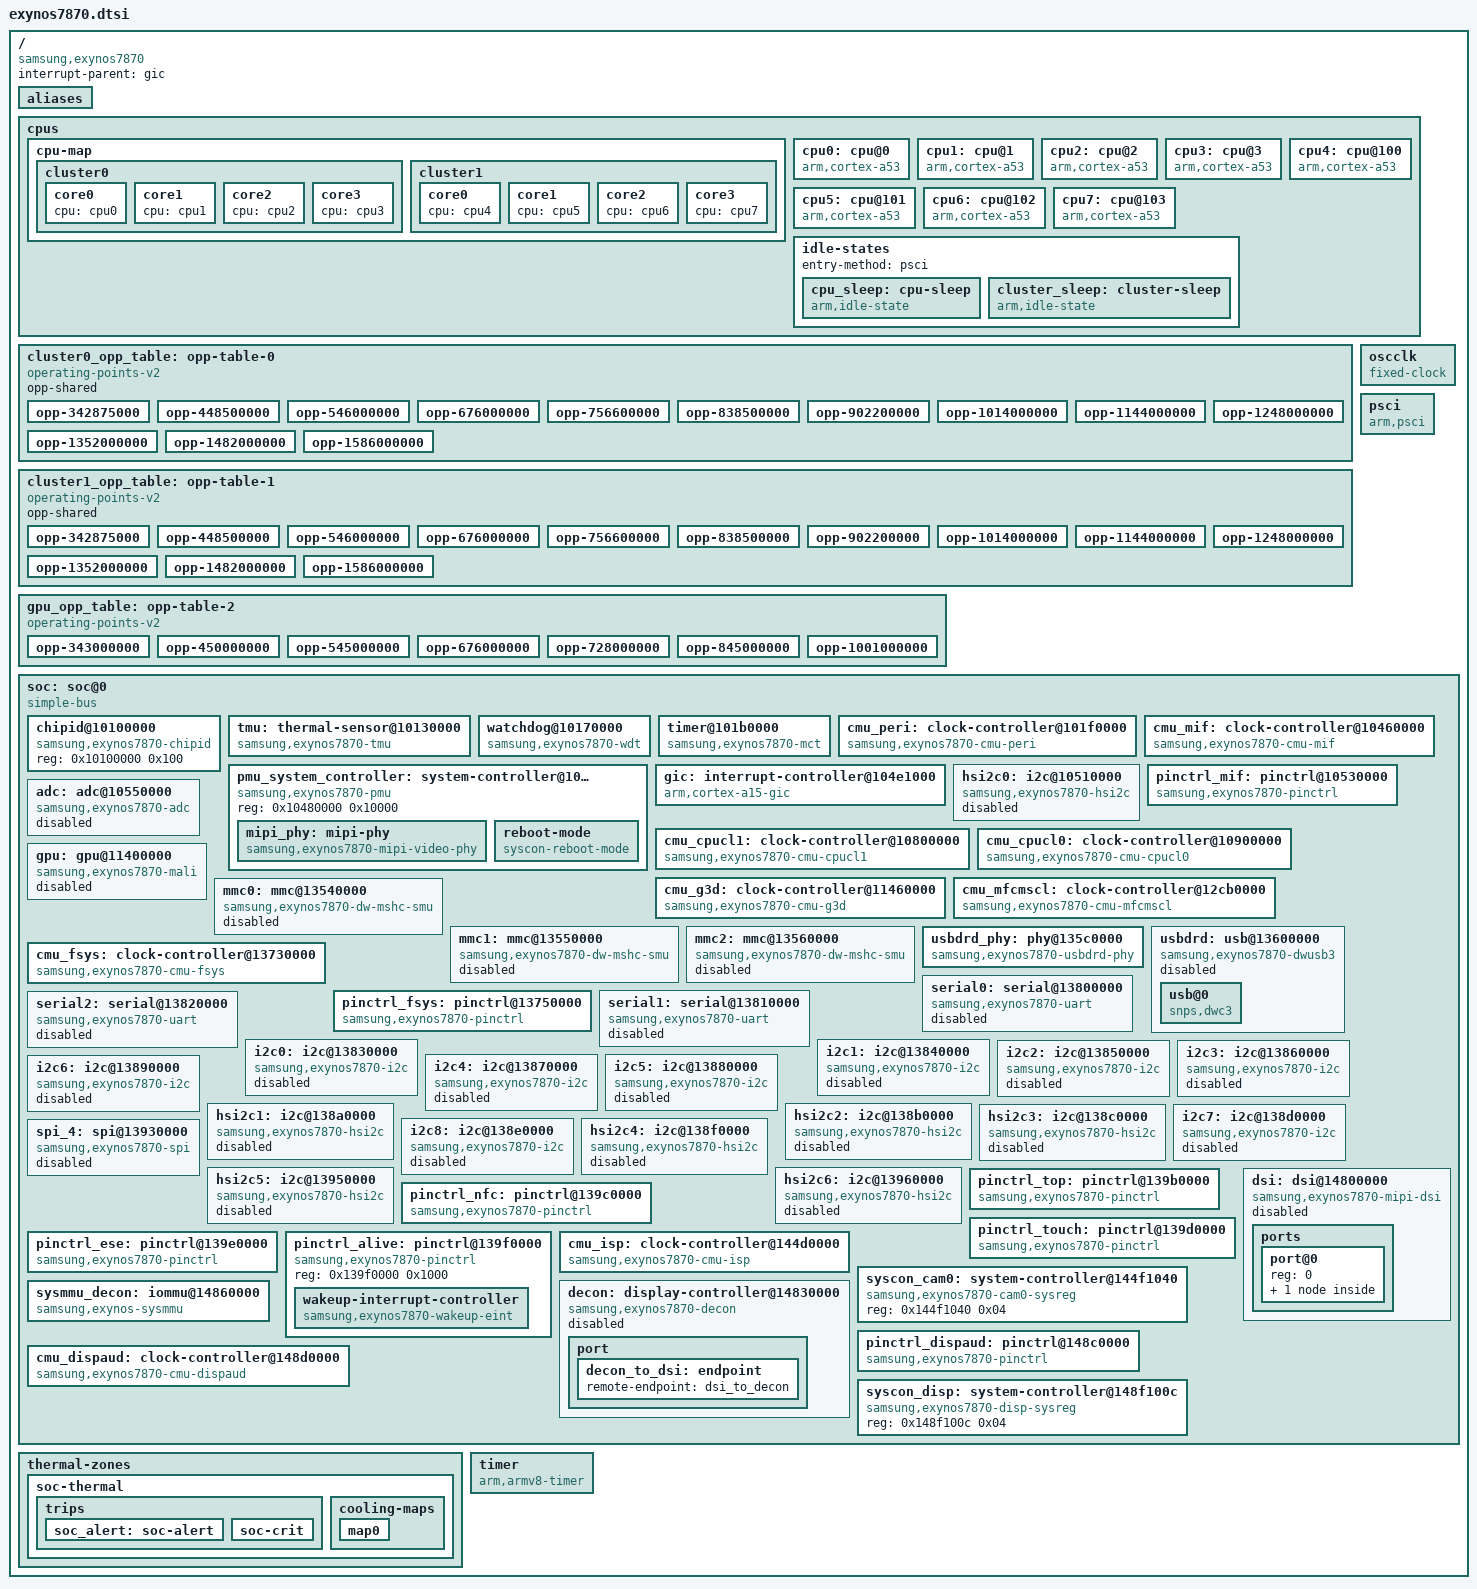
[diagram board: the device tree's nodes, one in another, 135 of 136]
// SPDX-License-Identifier: GPL-2.0
/*
 * Samsung Exynos7870 SoC device tree source
 *
 * Copyright (c) 2015 Samsung Electronics Co., Ltd.
 * Copyright (c) 2025 Kaustabh Chakraborty <kauschluss@disroot.org>
 */

#include <dt-bindings/clock/samsung,exynos7870-cmu.h>
#include <dt-bindings/interrupt-controller/arm-gic.h>
#include <dt-bindings/thermal/thermal.h>

/ {
	compatible = "samsung,exynos7870";
	#address-cells = <2>;
	#size-cells = <1>;

	interrupt-parent = <&gic>;

	aliases {
		pinctrl0 = &pinctrl_alive;
		pinctrl1 = &pinctrl_dispaud;
		pinctrl2 = &pinctrl_ese;
		pinctrl3 = &pinctrl_fsys;
		pinctrl4 = &pinctrl_mif;
		pinctrl5 = &pinctrl_nfc;
		pinctrl6 = &pinctrl_top;
		pinctrl7 = &pinctrl_touch;
	};

	cpus {
		#address-cells = <1>;
		#size-cells = <0>;

		cpu-map {
			cluster0 {
				core0 {
					cpu = <&cpu0>;
				};

				core1 {
					cpu = <&cpu1>;
				};

				core2 {
					cpu = <&cpu2>;
				};

				core3 {
					cpu = <&cpu3>;
				};
			};

			cluster1 {
				core0 {
					cpu = <&cpu4>;
				};

				core1 {
					cpu = <&cpu5>;
				};

				core2 {
					cpu = <&cpu6>;
				};

				core3 {
					cpu = <&cpu7>;
				};
			};
		};

		cpu0: cpu@0 {
			device_type = "cpu";
			compatible = "arm,cortex-a53";
			reg = <0x0>;
			clocks = <&cmu_cpucl0 CLK_CLUSTER0_SCLK>;
			cpu-idle-states = <&cpu_sleep>;
			enable-method = "psci";
			operating-points-v2 = <&cluster0_opp_table>;
			#cooling-cells = <2>;
		};

		cpu1: cpu@1 {
			device_type = "cpu";
			compatible = "arm,cortex-a53";
			reg = <0x1>;
			clocks = <&cmu_cpucl0 CLK_CLUSTER0_SCLK>;
			cpu-idle-states = <&cpu_sleep>;
			enable-method = "psci";
			operating-points-v2 = <&cluster0_opp_table>;
			#cooling-cells = <2>;
		};

		cpu2: cpu@2 {
			device_type = "cpu";
			compatible = "arm,cortex-a53";
			reg = <0x2>;
			clocks = <&cmu_cpucl0 CLK_CLUSTER0_SCLK>;
			cpu-idle-states = <&cpu_sleep>;
			enable-method = "psci";
			operating-points-v2 = <&cluster0_opp_table>;
			#cooling-cells = <2>;
		};

		cpu3: cpu@3 {
			device_type = "cpu";
			compatible = "arm,cortex-a53";
			reg = <0x3>;
			clocks = <&cmu_cpucl0 CLK_CLUSTER0_SCLK>;
			cpu-idle-states = <&cpu_sleep>;
			enable-method = "psci";
			operating-points-v2 = <&cluster0_opp_table>;
			#cooling-cells = <2>;
		};

		cpu4: cpu@100 {
			device_type = "cpu";
			compatible = "arm,cortex-a53";
			reg = <0x100>;
			clocks = <&cmu_cpucl1 CLK_CLUSTER1_SCLK>;
			cpu-idle-states = <&cpu_sleep>, <&cluster_sleep>;
			enable-method = "psci";
			operating-points-v2 = <&cluster1_opp_table>;
			#cooling-cells = <2>;
		};

		cpu5: cpu@101 {
			device_type = "cpu";
			compatible = "arm,cortex-a53";
			reg = <0x101>;
			clocks = <&cmu_cpucl1 CLK_CLUSTER1_SCLK>;
			cpu-idle-states = <&cpu_sleep>, <&cluster_sleep>;
			enable-method = "psci";
			operating-points-v2 = <&cluster1_opp_table>;
			#cooling-cells = <2>;
		};

		cpu6: cpu@102 {
			device_type = "cpu";
			compatible = "arm,cortex-a53";
			reg = <0x102>;
			clocks = <&cmu_cpucl1 CLK_CLUSTER1_SCLK>;
			cpu-idle-states = <&cpu_sleep>, <&cluster_sleep>;
			enable-method = "psci";
			operating-points-v2 = <&cluster1_opp_table>;
			#cooling-cells = <2>;
		};

		cpu7: cpu@103 {
			device_type = "cpu";
			compatible = "arm,cortex-a53";
			reg = <0x103>;
			clocks = <&cmu_cpucl1 CLK_CLUSTER1_SCLK>;
			cpu-idle-states = <&cpu_sleep>, <&cluster_sleep>;
			enable-method = "psci";
			operating-points-v2 = <&cluster1_opp_table>;
			#cooling-cells = <2>;
		};

		idle-states {
			entry-method = "psci";

			cpu_sleep: cpu-sleep {
				compatible = "arm,idle-state";
				arm,psci-suspend-param = <0x10000>;
				local-timer-stop;
				entry-latency-us = <35>;
				exit-latency-us = <90>;
				min-residency-us = <750>;
			};

			cluster_sleep: cluster-sleep {
				compatible = "arm,idle-state";
				arm,psci-suspend-param = <0x1010000>;
				local-timer-stop;
				entry-latency-us = <150>;
				exit-latency-us = <250>;
				min-residency-us = <3000>;
			};
		};
	};

	cluster0_opp_table: opp-table-0 {
		compatible = "operating-points-v2";
		opp-shared;

		opp-342875000 {
			opp-hz = /bits/ 64 <342875000>;
			opp-microvolt = <687500 687500 1175000>;
			clock-latency-ns = <100000>;
		};

		opp-448500000 {
			opp-hz = /bits/ 64 <448500000>;
			opp-microvolt = <712500 712500 1175000>;
			clock-latency-ns = <100000>;
		};

		opp-546000000 {
			opp-hz = /bits/ 64 <546000000>;
			opp-microvolt = <743750 743750 1175000>;
			clock-latency-ns = <100000>;
		};

		opp-676000000 {
			opp-hz = /bits/ 64 <676000000>;
			opp-microvolt = <775000 775000 1175000>;
			clock-latency-ns = <100000>;
		};

		opp-756600000 {
			opp-hz = /bits/ 64 <756600000>;
			opp-microvolt = <806250 806250 1175000>;
			clock-latency-ns = <100000>;
		};

		opp-838500000 {
			opp-hz = /bits/ 64 <838500000>;
			opp-microvolt = <837500 837500 1175000>;
			clock-latency-ns = <100000>;
		};

		opp-902200000 {
			opp-hz = /bits/ 64 <902200000>;
			opp-microvolt = <875000 875000 1175000>;
			clock-latency-ns = <100000>;
		};

		opp-1014000000 {
			opp-hz = /bits/ 64 <1014000000>;
			opp-microvolt = <900000 900000 1175000>;
			clock-latency-ns = <100000>;
		};

		opp-1144000000 {
			opp-hz = /bits/ 64 <1144000000>;
			opp-microvolt = <950000 950000 1175000>;
			clock-latency-ns = <100000>;
		};

		opp-1248000000 {
			opp-hz = /bits/ 64 <1248000000>;
			opp-microvolt = <1000000 1000000 1175000>;
			clock-latency-ns = <100000>;
		};

		opp-1352000000 {
			opp-hz = /bits/ 64 <1352000000>;
			opp-microvolt = <1050000 1050000 1175000>;
			clock-latency-ns = <100000>;
		};

		opp-1482000000 {
			opp-hz = /bits/ 64 <1482000000>;
			opp-microvolt = <1112500 1112500 1175000>;
			clock-latency-ns = <100000>;
		};

		opp-1586000000 {
			opp-hz = /bits/ 64 <1586000000>;
			opp-microvolt = <1175000 1175000 1175000>;
			clock-latency-ns = <100000>;
		};
	};

	cluster1_opp_table: opp-table-1 {
		compatible = "operating-points-v2";
		opp-shared;

		opp-342875000 {
			opp-hz = /bits/ 64 <342875000>;
			opp-microvolt = <687500 687500 1175000>;
			clock-latency-ns = <100000>;
		};

		opp-448500000 {
			opp-hz = /bits/ 64 <448500000>;
			opp-microvolt = <712500 712500 1175000>;
			clock-latency-ns = <100000>;
		};

		opp-546000000 {
			opp-hz = /bits/ 64 <546000000>;
			opp-microvolt = <743750 743750 1175000>;
			clock-latency-ns = <100000>;
		};

		opp-676000000 {
			opp-hz = /bits/ 64 <676000000>;
			opp-microvolt = <775000 775000 1175000>;
			clock-latency-ns = <100000>;
		};

		opp-756600000 {
			opp-hz = /bits/ 64 <756600000>;
			opp-microvolt = <806250 806250 1175000>;
			clock-latency-ns = <100000>;
		};

		opp-838500000 {
			opp-hz = /bits/ 64 <838500000>;
			opp-microvolt = <837500 837500 1175000>;
			clock-latency-ns = <100000>;
		};

		opp-902200000 {
			opp-hz = /bits/ 64 <902200000>;
			opp-microvolt = <875000 875000 1175000>;
			clock-latency-ns = <100000>;
		};

		opp-1014000000 {
			opp-hz = /bits/ 64 <1014000000>;
			opp-microvolt = <900000 900000 1175000>;
			clock-latency-ns = <100000>;
		};

		opp-1144000000 {
			opp-hz = /bits/ 64 <1144000000>;
			opp-microvolt = <950000 950000 1175000>;
			clock-latency-ns = <100000>;
		};

		opp-1248000000 {
			opp-hz = /bits/ 64 <1248000000>;
			opp-microvolt = <1000000 1000000 1175000>;
			clock-latency-ns = <100000>;
		};

		opp-1352000000 {
			opp-hz = /bits/ 64 <1352000000>;
			opp-microvolt = <1050000 1050000 1175000>;
			clock-latency-ns = <100000>;
		};

		opp-1482000000 {
			opp-hz = /bits/ 64 <1482000000>;
			opp-microvolt = <1112500 1112500 1175000>;
			clock-latency-ns = <100000>;
		};

		opp-1586000000 {
			opp-hz = /bits/ 64 <1586000000>;
			opp-microvolt = <1175000 1175000 1175000>;
			clock-latency-ns = <100000>;
		};
	};

	oscclk: oscclk {
		compatible = "fixed-clock";
		#clock-cells = <0>;
	};

	gpu_opp_table: opp-table-2 {
		compatible = "operating-points-v2";

		opp-343000000 {
			opp-hz = /bits/ 64 <343000000>;
			opp-microvolt = <750000 750000 1006250>;
		};

		opp-450000000 {
			opp-hz = /bits/ 64 <450000000>;
			opp-microvolt = <750000 750000 1006250>;
		};

		opp-545000000 {
			opp-hz = /bits/ 64 <545000000>;
			opp-microvolt = <750000 750000 1006250>;
		};

		opp-676000000 {
			opp-hz = /bits/ 64 <676000000>;
			opp-microvolt = <812500 812500 1006250>;
		};

		opp-728000000 {
			opp-hz = /bits/ 64 <728000000>;
			opp-microvolt = <875000 875000 1006250>;
		};

		opp-845000000 {
			opp-hz = /bits/ 64 <845000000>;
			opp-microvolt = <925000 925000 1006250>;
		};

		opp-1001000000 {
			opp-hz = /bits/ 64 <1001000000>;
			opp-microvolt = <1006250 1006250 1006250>;
		};
	};

	psci {
		compatible = "arm,psci";
		method = "smc";
		cpu_suspend = <0xc4000001>;
		cpu_off = <0x84000002>;
		cpu_on = <0xc4000003>;
	};

	soc: soc@0 {
		compatible = "simple-bus";
		ranges = <0x0 0x0 0x0 0x20000000>;
		#address-cells = <1>;
		#size-cells = <1>;

		chipid@10100000 {
			compatible = "samsung,exynos7870-chipid",
				     "samsung,exynos4210-chipid";
			reg = <0x10100000 0x100>;
		};

		tmu: thermal-sensor@10130000 {
			compatible = "samsung,exynos7870-tmu";
			reg = <0x10130000 0x200>;
			interrupts = <GIC_SPI 435 IRQ_TYPE_LEVEL_HIGH>;
			clocks = <&cmu_peri CLK_GOUT_PERI_SFRIF_TMU_PCLK>,
				 <&cmu_peri CLK_GOUT_PERI_TMU_CLK>;
			clock-names = "tmu_apbif", "tmu_sclk";
			#thermal-sensor-cells = <0>;
		};

		watchdog@10170000 {
			compatible = "samsung,exynos7870-wdt", "samsung,exynos7-wdt";
			reg = <0x10170000 0x100>;
			interrupts = <GIC_SPI 100 IRQ_TYPE_LEVEL_HIGH>;
			clocks = <&cmu_peri CLK_GOUT_PERI_WDT_CPUCL0_PCLK>;
			clock-names = "watchdog";
			samsung,syscon-phandle = <&pmu_system_controller>;
		};

		timer@101b0000 {
			compatible = "samsung,exynos7870-mct",
				     "samsung,exynos4210-mct";
			reg = <0x101b0000 0x800>;
			interrupts = <GIC_SPI 102 IRQ_TYPE_LEVEL_HIGH>,
				     <GIC_SPI 103 IRQ_TYPE_LEVEL_HIGH>,
				     <GIC_SPI 104 IRQ_TYPE_LEVEL_HIGH>,
				     <GIC_SPI 105 IRQ_TYPE_LEVEL_HIGH>,
				     <GIC_SPI 106 IRQ_TYPE_LEVEL_HIGH>,
				     <GIC_SPI 107 IRQ_TYPE_LEVEL_HIGH>,
				     <GIC_SPI 108 IRQ_TYPE_LEVEL_HIGH>,
				     <GIC_SPI 109 IRQ_TYPE_LEVEL_HIGH>,
				     <GIC_SPI 110 IRQ_TYPE_LEVEL_HIGH>,
				     <GIC_SPI 111 IRQ_TYPE_LEVEL_HIGH>,
				     <GIC_SPI 112 IRQ_TYPE_LEVEL_HIGH>,
				     <GIC_SPI 113 IRQ_TYPE_LEVEL_HIGH>;
			clocks = <&oscclk>, <&cmu_peri CLK_GOUT_PERI_MCT_PCLK>;
			clock-names = "fin_pll", "mct";
		};

		cmu_peri: clock-controller@101f0000 {
			compatible = "samsung,exynos7870-cmu-peri";
			reg = <0x101f0000 0x1000>;
			#clock-cells = <1>;

			clocks = <&oscclk>,
				 <&cmu_mif CLK_GOUT_MIF_CMU_PERI_BUS>,
				 <&cmu_mif CLK_GOUT_MIF_CMU_PERI_SPI0>,
				 <&cmu_mif CLK_GOUT_MIF_CMU_PERI_SPI1>,
				 <&cmu_mif CLK_GOUT_MIF_CMU_PERI_SPI2>,
				 <&cmu_mif CLK_GOUT_MIF_CMU_PERI_SPI3>,
				 <&cmu_mif CLK_GOUT_MIF_CMU_PERI_SPI4>,
				 <&cmu_mif CLK_GOUT_MIF_CMU_PERI_UART0>,
				 <&cmu_mif CLK_GOUT_MIF_CMU_PERI_UART1>,
				 <&cmu_mif CLK_GOUT_MIF_CMU_PERI_UART2>;
			clock-names = "oscclk", "bus", "spi0", "spi1", "spi2",
				      "spi3", "spi4", "uart0", "uart1", "uart2";
		};

		cmu_mif: clock-controller@10460000 {
			compatible = "samsung,exynos7870-cmu-mif";
			reg = <0x10460000 0x1000>;
			#clock-cells = <1>;

			clocks = <&oscclk>;
			clock-names = "oscclk";
		};

		pmu_system_controller: system-controller@10480000 {
			compatible = "samsung,exynos7870-pmu",
				     "samsung,exynos7-pmu", "syscon";
			reg = <0x10480000 0x10000>;

			mipi_phy: mipi-phy {
				compatible = "samsung,exynos7870-mipi-video-phy";
				#phy-cells = <1>;

				samsung,cam0-sysreg = <&syscon_cam0>;
				samsung,disp-sysreg = <&syscon_disp>;
			};

			reboot-mode {
				compatible = "syscon-reboot-mode";
				offset = <0x080c>;
				mode-bootloader = <0x1234567d>;
				mode-download = <0x12345671>;
				mode-recovery = <0x12345674>;
			};
		};

		gic: interrupt-controller@104e1000 {
			compatible = "arm,cortex-a15-gic";
			reg = <0x104e1000 0x1000>,
			      <0x104e2000 0x1000>,
			      <0x104e4000 0x2000>,
			      <0x104e6000 0x2000>;
			interrupts = <GIC_PPI 9 (GIC_CPU_MASK_SIMPLE(8) | IRQ_TYPE_LEVEL_HIGH)>;
			interrupt-controller;
			#address-cells = <0>;
			#interrupt-cells = <3>;
		};

		hsi2c0: i2c@10510000 {
			compatible = "samsung,exynos7870-hsi2c",
				     "samsung,exynos7-hsi2c";
			reg = <0x10510000 0x2000>;
			interrupts = <GIC_SPI 371 IRQ_TYPE_LEVEL_HIGH>;

			pinctrl-0 = <&hsi2c0_bus>;
			pinctrl-names = "default";

			clocks = <&cmu_mif CLK_GOUT_MIF_HSI2C_IPCLK>;
			clock-names = "hsi2c";

			#address-cells = <1>;
			#size-cells = <0>;

			status = "disabled";
		};

		pinctrl_mif: pinctrl@10530000 {
			compatible = "samsung,exynos7870-pinctrl";
			reg = <0x10530000 0x1000>;
			interrupts = <GIC_SPI 392 IRQ_TYPE_LEVEL_HIGH>;
		};

		adc: adc@10550000 {
			compatible = "samsung,exynos7870-adc";
			reg = <0x10550000 0x1000>;
			interrupts = <GIC_SPI 395 IRQ_TYPE_LEVEL_HIGH>;
			#io-channel-cells = <1>;

			clocks = <&cmu_mif CLK_GOUT_MIF_WRAP_ADC_IF_OSC_SYS>;
			clock-names = "adc";

			status = "disabled";
		};

		cmu_cpucl1: clock-controller@10800000 {
			compatible = "samsung,exynos7870-cmu-cpucl1";
			reg = <0x10800000 0x1000>;
			#clock-cells = <1>;

			clocks = <&oscclk>,
				 <&cmu_mif CLK_GOUT_MIF_CMU_CPUCL1_SWITCH>;
			clock-names = "oscclk", "switch";
		};

		cmu_cpucl0: clock-controller@10900000 {
			compatible = "samsung,exynos7870-cmu-cpucl0";
			reg = <0x10900000 0x1000>;
			#clock-cells = <1>;

			clocks = <&oscclk>,
				 <&cmu_mif CLK_GOUT_MIF_CMU_CPUCL0_SWITCH>;
			clock-names = "oscclk", "switch";
		};

		gpu: gpu@11400000 {
			compatible = "samsung,exynos7870-mali", "arm,mali-t830";
			reg = <0x11400000 0x5000>;
			interrupts = <GIC_SPI 282 IRQ_TYPE_LEVEL_HIGH>,
				     <GIC_SPI 283 IRQ_TYPE_LEVEL_HIGH>,
				     <GIC_SPI 281 IRQ_TYPE_LEVEL_HIGH>;
			interrupt-names = "job", "mmu", "gpu";

			clocks = <&cmu_g3d CLK_GOUT_G3D_CLK>,
				 <&cmu_g3d CLK_GOUT_G3D_ASYNCS_D0_CLK>;
			clock-names = "core", "bus";
			operating-points-v2 = <&gpu_opp_table>;
			#cooling-cells = <2>;

			status = "disabled";
		};

		cmu_g3d: clock-controller@11460000 {
			compatible = "samsung,exynos7870-cmu-g3d";
			reg = <0x11460000 0x1000>;
			#clock-cells = <1>;

			clocks = <&oscclk>,
				 <&cmu_mif CLK_GOUT_MIF_CMU_G3D_SWITCH>;
			clock-names = "oscclk", "switch";
		};

		cmu_mfcmscl: clock-controller@12cb0000 {
			compatible = "samsung,exynos7870-cmu-mfcmscl";
			reg = <0x12cb0000 0x1000>;
			#clock-cells = <1>;

			clocks = <&oscclk>,
				 <&cmu_mif CLK_GOUT_MIF_CMU_MFCMSCL_MFC>,
				 <&cmu_mif CLK_GOUT_MIF_CMU_MFCMSCL_MSCL>;
			clock-names = "oscclk", "mfc", "mscl";
		};

		mmc0: mmc@13540000 {
			compatible = "samsung,exynos7870-dw-mshc-smu";
			reg = <0x13540000 0x2000>;
			interrupts = <GIC_SPI 245 IRQ_TYPE_LEVEL_HIGH>;

			clocks = <&cmu_fsys CLK_GOUT_FSYS_MMC0_ACLK>,
				 <&cmu_mif CLK_GOUT_MIF_CMU_FSYS_MMC0>;
			clock-names = "biu", "ciu";

			status = "disabled";
		};

		mmc1: mmc@13550000 {
			compatible = "samsung,exynos7870-dw-mshc-smu";
			reg = <0x13550000 0x2000>;
			interrupts = <GIC_SPI 246 IRQ_TYPE_LEVEL_HIGH>;

			clocks = <&cmu_fsys CLK_GOUT_FSYS_MMC1_ACLK>,
				 <&cmu_mif CLK_GOUT_MIF_CMU_FSYS_MMC1>;
			clock-names = "biu", "ciu";

			status = "disabled";
		};

		mmc2: mmc@13560000 {
			compatible = "samsung,exynos7870-dw-mshc-smu";
			reg = <0x13560000 0x2000>;
			interrupts = <GIC_SPI 247 IRQ_TYPE_LEVEL_HIGH>;

			clocks = <&cmu_fsys CLK_GOUT_FSYS_MMC2_ACLK>,
				 <&cmu_mif CLK_GOUT_MIF_CMU_FSYS_MMC2>;
			clock-names = "biu", "ciu";

			status = "disabled";
		};

		usbdrd_phy: phy@135c0000 {
			compatible = "samsung,exynos7870-usbdrd-phy";
			reg = <0x135c0000 0x100>;
			#phy-cells = <1>;

			clocks = <&cmu_fsys CLK_GOUT_FSYS_MUX_USB20DRD_PHYCLOCK_USER>,
				 <&cmu_fsys CLK_GOUT_FSYS_MUX_USB_PLL>;
			clock-names = "phy", "ref";

			samsung,pmu-syscon = <&pmu_system_controller>;
		};

		usbdrd: usb@13600000 {
			compatible = "samsung,exynos7870-dwusb3";
			ranges = <0x0 0x13600000 0x10000>;
			#address-cells = <1>;
			#size-cells = <1>;

			clocks = <&cmu_fsys CLK_GOUT_FSYS_USB20DRD_ACLK_HSDRD>,
				 <&cmu_fsys CLK_GOUT_FSYS_USB20DRD_HSDRD_REF_CLK>,
				 <&cmu_fsys CLK_GOUT_FSYS_USB20DRD_HCLK_USB20_CTRL>;
			clock-names = "bus_early", "ref", "ctrl";

			status = "disabled";

			usb@0 {
				compatible = "snps,dwc3";
				reg = <0x0 0x10000>;
				interrupts = <GIC_SPI 230 IRQ_TYPE_LEVEL_HIGH>;

				phys = <&usbdrd_phy 0>;
				phy-names = "usb2-phy";

				usb-role-switch;
				snps,usb2-gadget-lpm-disable;
			};
		};

		cmu_fsys: clock-controller@13730000 {
			compatible = "samsung,exynos7870-cmu-fsys";
			reg = <0x13730000 0x1000>;
			#clock-cells = <1>;

			clocks = <&oscclk>,
				 <&cmu_mif CLK_GOUT_MIF_CMU_FSYS_BUS>,
				 <&cmu_mif CLK_GOUT_MIF_CMU_FSYS_USB20DRD_REFCLK>;
			clock-names = "oscclk", "bus", "usb20drd";
		};

		pinctrl_fsys: pinctrl@13750000 {
			compatible = "samsung,exynos7870-pinctrl";
			reg = <0x13750000 0x1000>;
			interrupts = <GIC_SPI 250 IRQ_TYPE_LEVEL_HIGH>;
		};

		serial0: serial@13800000 {
			compatible = "samsung,exynos7870-uart",
				     "samsung,exynos8895-uart";
			reg = <0x13800000 0x100>;
			interrupts = <GIC_SPI 421 IRQ_TYPE_LEVEL_HIGH>;

			pinctrl-0 = <&uart0_bus>;
			pinctrl-names = "default";

			clocks = <&cmu_peri CLK_GOUT_PERI_UART0_PCLK>,
				 <&cmu_peri CLK_GOUT_PERI_UART0_EXT_UCLK>;
			clock-names = "uart", "clk_uart_baud0";

			samsung,uart-fifosize = <16>;

			status = "disabled";
		};

		serial1: serial@13810000 {
			compatible = "samsung,exynos7870-uart",
				     "samsung,exynos8895-uart";
			reg = <0x13810000 0x100>;
			interrupts = <GIC_SPI 422 IRQ_TYPE_LEVEL_HIGH>;

			pinctrl-0 = <&uart1_bus>;
			pinctrl-names = "default";

			clocks = <&cmu_peri CLK_GOUT_PERI_UART1_PCLK>,
				 <&cmu_peri CLK_GOUT_PERI_UART1_EXT_UCLK>;
			clock-names = "uart", "clk_uart_baud0";

			samsung,uart-fifosize = <256>;

			status = "disabled";
		};

		serial2: serial@13820000 {
			compatible = "samsung,exynos7870-uart",
				     "samsung,exynos8895-uart";
			reg = <0x13820000 0x100>;
			interrupts = <GIC_SPI 423 IRQ_TYPE_LEVEL_HIGH>;

			pinctrl-0 = <&uart2_bus>;
			pinctrl-names = "default";

			clocks = <&cmu_peri CLK_GOUT_PERI_UART2_PCLK>,
				 <&cmu_peri CLK_GOUT_PERI_UART2_EXT_UCLK>;
			clock-names = "uart", "clk_uart_baud0";

			samsung,uart-fifosize = <256>;

			status = "disabled";
		};

		i2c0: i2c@13830000 {
			compatible = "samsung,exynos7870-i2c",
				     "samsung,s3c2440-i2c";
			reg = <0x13830000 0x100>;
			interrupts = <GIC_SPI 424 IRQ_TYPE_LEVEL_HIGH>;

			pinctrl-0 = <&i2c0_bus>;
			pinctrl-names = "default";

			clocks = <&cmu_peri CLK_GOUT_PERI_I2C0_PCLK>;
			clock-names = "i2c";

			#address-cells = <1>;
			#size-cells = <0>;

			status = "disabled";
		};

		i2c1: i2c@13840000 {
			compatible = "samsung,exynos7870-i2c",
				     "samsung,s3c2440-i2c";
			reg = <0x13840000 0x100>;
			interrupts = <GIC_SPI 425 IRQ_TYPE_LEVEL_HIGH>;

			pinctrl-0 = <&i2c1_bus>;
			pinctrl-names = "default";

			clocks = <&cmu_peri CLK_GOUT_PERI_I2C1_PCLK>;
			clock-names = "i2c";

			#address-cells = <1>;
			#size-cells = <0>;

			status = "disabled";
		};

		i2c2: i2c@13850000 {
			compatible = "samsung,exynos7870-i2c",
				     "samsung,s3c2440-i2c";
			reg = <0x13850000 0x100>;
			interrupts = <GIC_SPI 426 IRQ_TYPE_LEVEL_HIGH>;

			pinctrl-0 = <&i2c2_bus>;
			pinctrl-names = "default";

			clocks = <&cmu_peri CLK_GOUT_PERI_I2C2_PCLK>;
			clock-names = "i2c";

			#address-cells = <1>;
			#size-cells = <0>;

			status = "disabled";
		};

		i2c3: i2c@13860000 {
			compatible = "samsung,exynos7870-i2c",
				     "samsung,s3c2440-i2c";
			reg = <0x13860000 0x100>;
			interrupts = <GIC_SPI 427 IRQ_TYPE_LEVEL_HIGH>;

			pinctrl-0 = <&i2c3_bus>;
			pinctrl-names = "default";

			clocks = <&cmu_peri CLK_GOUT_PERI_I2C3_PCLK>;
			clock-names = "i2c";

			#address-cells = <1>;
			#size-cells = <0>;

			status = "disabled";
		};

		i2c4: i2c@13870000 {
			compatible = "samsung,exynos7870-i2c",
				     "samsung,s3c2440-i2c";
			reg = <0x13870000 0x100>;
			interrupts = <GIC_SPI 428 IRQ_TYPE_LEVEL_HIGH>;

			pinctrl-0 = <&i2c4_bus>;
			pinctrl-names = "default";

			clocks = <&cmu_peri CLK_GOUT_PERI_I2C4_PCLK>;
			clock-names = "i2c";

			#address-cells = <1>;
			#size-cells = <0>;

			status = "disabled";
		};

		i2c5: i2c@13880000 {
			compatible = "samsung,exynos7870-i2c",
				     "samsung,s3c2440-i2c";
			reg = <0x13880000 0x100>;
			interrupts = <GIC_SPI 429 IRQ_TYPE_LEVEL_HIGH>;

			pinctrl-0 = <&i2c5_bus>;
			pinctrl-names = "default";

			clocks = <&cmu_peri CLK_GOUT_PERI_I2C5_PCLK>;
			clock-names = "i2c";

			#address-cells = <1>;
			#size-cells = <0>;

			status = "disabled";
		};

		i2c6: i2c@13890000 {
			compatible = "samsung,exynos7870-i2c",
				     "samsung,s3c2440-i2c";
			reg = <0x13890000 0x100>;
			interrupts = <GIC_SPI 430 IRQ_TYPE_LEVEL_HIGH>;

			pinctrl-0 = <&i2c6_bus>;
			pinctrl-names = "default";

			clocks = <&cmu_peri CLK_GOUT_PERI_I2C6_PCLK>;
			clock-names = "i2c";

			#address-cells = <1>;
			#size-cells = <0>;

			status = "disabled";
		};

		hsi2c1: i2c@138a0000 {
			compatible = "samsung,exynos7870-hsi2c",
				     "samsung,exynos7-hsi2c";
			reg = <0x138a0000 0x1000>;
			interrupts = <GIC_SPI 449 IRQ_TYPE_LEVEL_HIGH>;

			pinctrl-0 = <&hsi2c1_bus>;
			pinctrl-names = "default";

			clocks = <&cmu_peri CLK_GOUT_PERI_HSI2C1_IPCLK>;
			clock-names = "hsi2c";

			#address-cells = <1>;
			#size-cells = <0>;

			status = "disabled";
		};

		hsi2c2: i2c@138b0000 {
			compatible = "samsung,exynos7870-hsi2c",
				     "samsung,exynos7-hsi2c";
			reg = <0x138b0000 0x1000>;
			interrupts = <GIC_SPI 450 IRQ_TYPE_LEVEL_HIGH>;

			pinctrl-0 = <&hsi2c2_bus>;
			pinctrl-names = "default";

			clocks = <&cmu_peri CLK_GOUT_PERI_HSI2C2_IPCLK>;
			clock-names = "hsi2c";

			#address-cells = <1>;
			#size-cells = <0>;

			status = "disabled";
		};

		hsi2c3: i2c@138c0000 {
			compatible = "samsung,exynos7870-hsi2c",
				     "samsung,exynos7-hsi2c";
			reg = <0x138c0000 0x1000>;
			interrupts = <GIC_SPI 451 IRQ_TYPE_LEVEL_HIGH>;

			pinctrl-0 = <&hsi2c3_bus>;
			pinctrl-names = "default";

			clocks = <&cmu_peri CLK_GOUT_PERI_HSI2C3_IPCLK>;
			clock-names = "hsi2c";

			#address-cells = <1>;
			#size-cells = <0>;

			status = "disabled";
		};

		i2c7: i2c@138d0000 {
			compatible = "samsung,exynos7870-i2c",
				     "samsung,s3c2440-i2c";
			reg = <0x138d0000 0x100>;
			interrupts = <GIC_SPI 453 IRQ_TYPE_LEVEL_HIGH>;

			pinctrl-0 = <&i2c7_bus>;
			pinctrl-names = "default";

			clocks = <&cmu_peri CLK_GOUT_PERI_I2C7_PCLK>;
			clock-names = "i2c";

			#address-cells = <1>;
			#size-cells = <0>;

			status = "disabled";
		};

		i2c8: i2c@138e0000 {
			compatible = "samsung,exynos7870-i2c",
				     "samsung,s3c2440-i2c";
			reg = <0x138e0000 0x100>;
			interrupts = <GIC_SPI 454 IRQ_TYPE_LEVEL_HIGH>;

			pinctrl-0 = <&i2c8_bus>;
			pinctrl-names = "default";

			clocks = <&cmu_peri CLK_GOUT_PERI_I2C8_PCLK>;
			clock-names = "i2c";

			#address-cells = <1>;
			#size-cells = <0>;

			status = "disabled";
		};

		hsi2c4: i2c@138f0000 {
			compatible = "samsung,exynos7870-hsi2c",
				     "samsung,exynos7-hsi2c";
			reg = <0x138f0000 0x1000>;
			interrupts = <GIC_SPI 456 IRQ_TYPE_LEVEL_HIGH>;

			pinctrl-0 = <&hsi2c4_bus>;
			pinctrl-names = "default";

			clocks = <&cmu_peri CLK_GOUT_PERI_HSI2C4_IPCLK>;
			clock-names = "hsi2c";

			#address-cells = <1>;
			#size-cells = <0>;

			status = "disabled";
		};

		spi_4: spi@13930000 {
			compatible = "samsung,exynos7870-spi";
			reg = <0x13930000 0x100>;
			interrupts = <GIC_SPI 455 IRQ_TYPE_LEVEL_HIGH>;

			pinctrl-0 = <&spi4_bus>, <&spi4_cs_func>;
			pinctrl-names = "default";

			clocks = <&cmu_peri CLK_GOUT_PERI_SPI4_PCLK>,
				 <&cmu_peri CLK_GOUT_PERI_SPI4_SPI_EXT_CLK>;
			clock-names = "spi", "spi_busclk0";
			/*
			 * From the bus PLL (799.5 MHz) the 6-bit divider cannot
			 * go below 12.5 MHz, i.e. 6.25 MHz SCK.
			 */
			assigned-clocks = <&cmu_mif CLK_MOUT_MIF_CMU_PERI_SPI4>;
			assigned-clock-parents = <&oscclk>;

			num-cs = <1>;
			#address-cells = <1>;
			#size-cells = <0>;

			status = "disabled";
		};

		hsi2c5: i2c@13950000 {
			compatible = "samsung,exynos7870-hsi2c",
				     "samsung,exynos7-hsi2c";
			reg = <0x13950000 0x1000>;
			interrupts = <GIC_SPI 457 IRQ_TYPE_LEVEL_HIGH>;

			pinctrl-0 = <&hsi2c5_bus>;
			pinctrl-names = "default";

			clocks = <&cmu_peri CLK_GOUT_PERI_HSI2C5_IPCLK>;
			clock-names = "hsi2c";

			#address-cells = <1>;
			#size-cells = <0>;

			status = "disabled";
		};

		hsi2c6: i2c@13960000 {
			compatible = "samsung,exynos7870-hsi2c",
				     "samsung,exynos7-hsi2c";
			reg = <0x13960000 0x1000>;
			interrupts = <GIC_SPI 458 IRQ_TYPE_LEVEL_HIGH>;

			pinctrl-0 = <&hsi2c6_bus>;
			pinctrl-names = "default";

			clocks = <&cmu_peri CLK_GOUT_PERI_HSI2C6_IPCLK>;
			clock-names = "hsi2c";

			#address-cells = <1>;
			#size-cells = <0>;

			status = "disabled";
		};

		pinctrl_top: pinctrl@139b0000 {
			compatible = "samsung,exynos7870-pinctrl";
			reg = <0x139b0000 0x1000>;
			interrupts = <GIC_SPI 438 IRQ_TYPE_LEVEL_HIGH>;
		};

		pinctrl_nfc: pinctrl@139c0000 {
			compatible = "samsung,exynos7870-pinctrl";
			reg = <0x139c0000 0x1000>;
			interrupts = <GIC_SPI 439 IRQ_TYPE_LEVEL_HIGH>;
		};

		pinctrl_touch: pinctrl@139d0000 {
			compatible = "samsung,exynos7870-pinctrl";
			reg = <0x139d0000 0x1000>;
			interrupts = <GIC_SPI 440 IRQ_TYPE_LEVEL_HIGH>;
		};

		pinctrl_ese: pinctrl@139e0000 {
			compatible = "samsung,exynos7870-pinctrl";
			reg = <0x139e0000 0x1000>;
			interrupts = <GIC_SPI 441 IRQ_TYPE_LEVEL_HIGH>;
		};

		pinctrl_alive: pinctrl@139f0000 {
			compatible = "samsung,exynos7870-pinctrl";
			reg = <0x139f0000 0x1000>;

			wakeup-interrupt-controller {
				compatible = "samsung,exynos7870-wakeup-eint",
					     "samsung,exynos7-wakeup-eint";
				interrupt-parent = <&gic>;
				interrupts = <GIC_SPI 16 IRQ_TYPE_LEVEL_HIGH>;
			};
		};

		cmu_isp: clock-controller@144d0000 {
			compatible = "samsung,exynos7870-cmu-isp";
			reg = <0x144d0000 0x1000>;
			#clock-cells = <1>;

			clocks = <&oscclk>,
				 <&cmu_mif CLK_GOUT_MIF_CMU_ISP_CAM>,
				 <&cmu_mif CLK_GOUT_MIF_CMU_ISP_ISP>,
				 <&cmu_mif CLK_GOUT_MIF_CMU_ISP_VRA>;
			clock-names = "oscclk", "cam", "isp", "vra";
		};

		syscon_cam0: system-controller@144f1040 {
			compatible = "samsung,exynos7870-cam0-sysreg", "syscon";
			reg = <0x144f1040 0x04>;
		};

		dsi: dsi@14800000 {
			compatible = "samsung,exynos7870-mipi-dsi";
			reg = <0x14800000 0x100>;
			interrupts = <GIC_SPI 207 IRQ_TYPE_LEVEL_HIGH>;

			clocks = <&cmu_dispaud CLK_GOUT_DISPAUD_BUS_DISP>,
				 <&cmu_dispaud CLK_GOUT_DISPAUD_APB_DISP>,
				 <&cmu_dispaud CLK_GOUT_DISPAUD_MUX_MIPIPHY_TXBYTECLKHS_USER>,
				 <&cmu_dispaud CLK_GOUT_DISPAUD_MUX_MIPIPHY_RXCLKESC0_USER>;
			clock-names = "bus", "pll", "byte", "esc";

			phys = <&mipi_phy 1>;
			phy-names = "dsim";

			status = "disabled";

			ports {
				#address-cells = <1>;
				#size-cells = <0>;

				port@0 {
					reg = <0>;

					dsi_to_decon: endpoint {
						remote-endpoint = <&decon_to_dsi>;
					};
				};
			};
		};

		decon: display-controller@14830000 {
			compatible = "samsung,exynos7870-decon";
			reg = <0x14830000 0x8000>;
			interrupts = <GIC_SPI 201 IRQ_TYPE_LEVEL_HIGH>,
				     <GIC_SPI 202 IRQ_TYPE_LEVEL_HIGH>,
				     <GIC_SPI 203 IRQ_TYPE_LEVEL_HIGH>;
			interrupt-names = "fifo", "vsync", "lcd_sys";

			clocks = <&cmu_dispaud CLK_GOUT_DISPAUD_MUX_PLL>,
				 <&cmu_dispaud CLK_GOUT_DISPAUD_MUX_BUS_USER>,
				 <&cmu_dispaud CLK_GOUT_DISPAUD_MUX_DECON_ECLK>,
				 <&cmu_dispaud CLK_GOUT_DISPAUD_MUX_DECON_VCLK>;
			clock-names = "pclk_decon0", "aclk_decon0",
				      "decon0_eclk", "decon0_vclk";

			iommus = <&sysmmu_decon>;

			status = "disabled";

			port {
				decon_to_dsi: endpoint {
					remote-endpoint = <&dsi_to_decon>;
				};
			};
		};

		sysmmu_decon: iommu@14860000 {
			compatible = "samsung,exynos-sysmmu";
			reg = <0x14860000 0x1000>;
			interrupts = <GIC_SPI 193 IRQ_TYPE_LEVEL_HIGH>;
			#iommu-cells = <0>;

			clocks = <&cmu_dispaud CLK_GOUT_DISPAUD_MUX_BUS_USER>;
			clock-names = "sysmmu";
		};

		pinctrl_dispaud: pinctrl@148c0000 {
			compatible = "samsung,exynos7870-pinctrl";
			reg = <0x148c0000 0x1000>;
			interrupts = <GIC_SPI 68 IRQ_TYPE_LEVEL_HIGH>;
		};

		cmu_dispaud: clock-controller@148d0000 {
			compatible = "samsung,exynos7870-cmu-dispaud";
			reg = <0x148d0000 0x1000>;
			#clock-cells = <1>;

			clocks = <&oscclk>,
				 <&cmu_mif CLK_GOUT_MIF_CMU_DISPAUD_BUS>,
				 <&cmu_mif CLK_GOUT_MIF_CMU_DISPAUD_DECON_ECLK>,
				 <&cmu_mif CLK_GOUT_MIF_CMU_DISPAUD_DECON_VCLK>;
			clock-names = "oscclk", "bus", "decon_eclk", "decon_vclk";
		};

		syscon_disp: system-controller@148f100c {
			compatible = "samsung,exynos7870-disp-sysreg", "syscon";
			reg = <0x148f100c 0x04>;
		};
	};

	thermal-zones {
		soc-thermal {
			polling-delay-passive = <250>;
			polling-delay = <0>;
			thermal-sensors = <&tmu>;

			trips {
				soc_alert: soc-alert {
					temperature = <76000>;
					hysteresis = <2000>;
					type = "passive";
				};

				soc-crit {
					temperature = <110000>;
					hysteresis = <0>;
					type = "critical";
				};
			};

			cooling-maps {
				map0 {
					trip = <&soc_alert>;
					cooling-device =
						<&cpu0 THERMAL_NO_LIMIT THERMAL_NO_LIMIT>,
						<&cpu4 THERMAL_NO_LIMIT THERMAL_NO_LIMIT>,
						<&gpu THERMAL_NO_LIMIT THERMAL_NO_LIMIT>;
				};
			};
		};
	};

	timer {
		compatible = "arm,armv8-timer";
		interrupts = <GIC_PPI 13 (GIC_CPU_MASK_SIMPLE(8) | IRQ_TYPE_LEVEL_LOW)>,
			     <GIC_PPI 14 (GIC_CPU_MASK_SIMPLE(8) | IRQ_TYPE_LEVEL_LOW)>,
			     <GIC_PPI 11 (GIC_CPU_MASK_SIMPLE(8) | IRQ_TYPE_LEVEL_LOW)>,
			     <GIC_PPI 10 (GIC_CPU_MASK_SIMPLE(8) | IRQ_TYPE_LEVEL_LOW)>;

		/*
		 * Non-updatable, broken stock Samsung bootloader does not
		 * configure CNTFRQ_EL0
		 */
		clock-frequency = <26000000>;
	};
};

#include "exynos7870-pinctrl.dtsi"
#include "arm/samsung/exynos-syscon-restart.dtsi"
